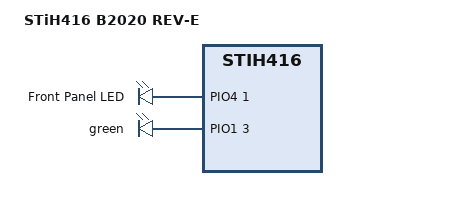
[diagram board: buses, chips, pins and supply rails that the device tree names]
/*
 * Copyright (C) 2014 STMicroelectronics (R&D) Limited.
 * Author: Lee Jones <lee.jones@linaro.org>
 *
 * This program is free software; you can redistribute it and/or modify
 * it under the terms of the GNU General Public License version 2 as
 * publishhed by the Free Software Foundation.
 */
/dts-v1/;
#include "stih416.dtsi"
#include "stih41x-b2020.dtsi"
/ {
	model = "STiH416 B2020 REV-E";
	compatible = "st,stih416-b2020", "st,stih416";

	soc {
		leds {
			compatible = "gpio-leds";
			red {
				#gpio-cells		= <1>;
				label			= "Front Panel LED";
				gpios			= <&PIO4 1>;
				linux,default-trigger	= "heartbeat";
			};
			green {
				gpios			= <&PIO1 3>;
				default-state 		= "off";
			};
		};

		ethernet1: dwmac@fef08000 {
			snps,reset-gpio = <&PIO0 7>;
		};
	};
};
